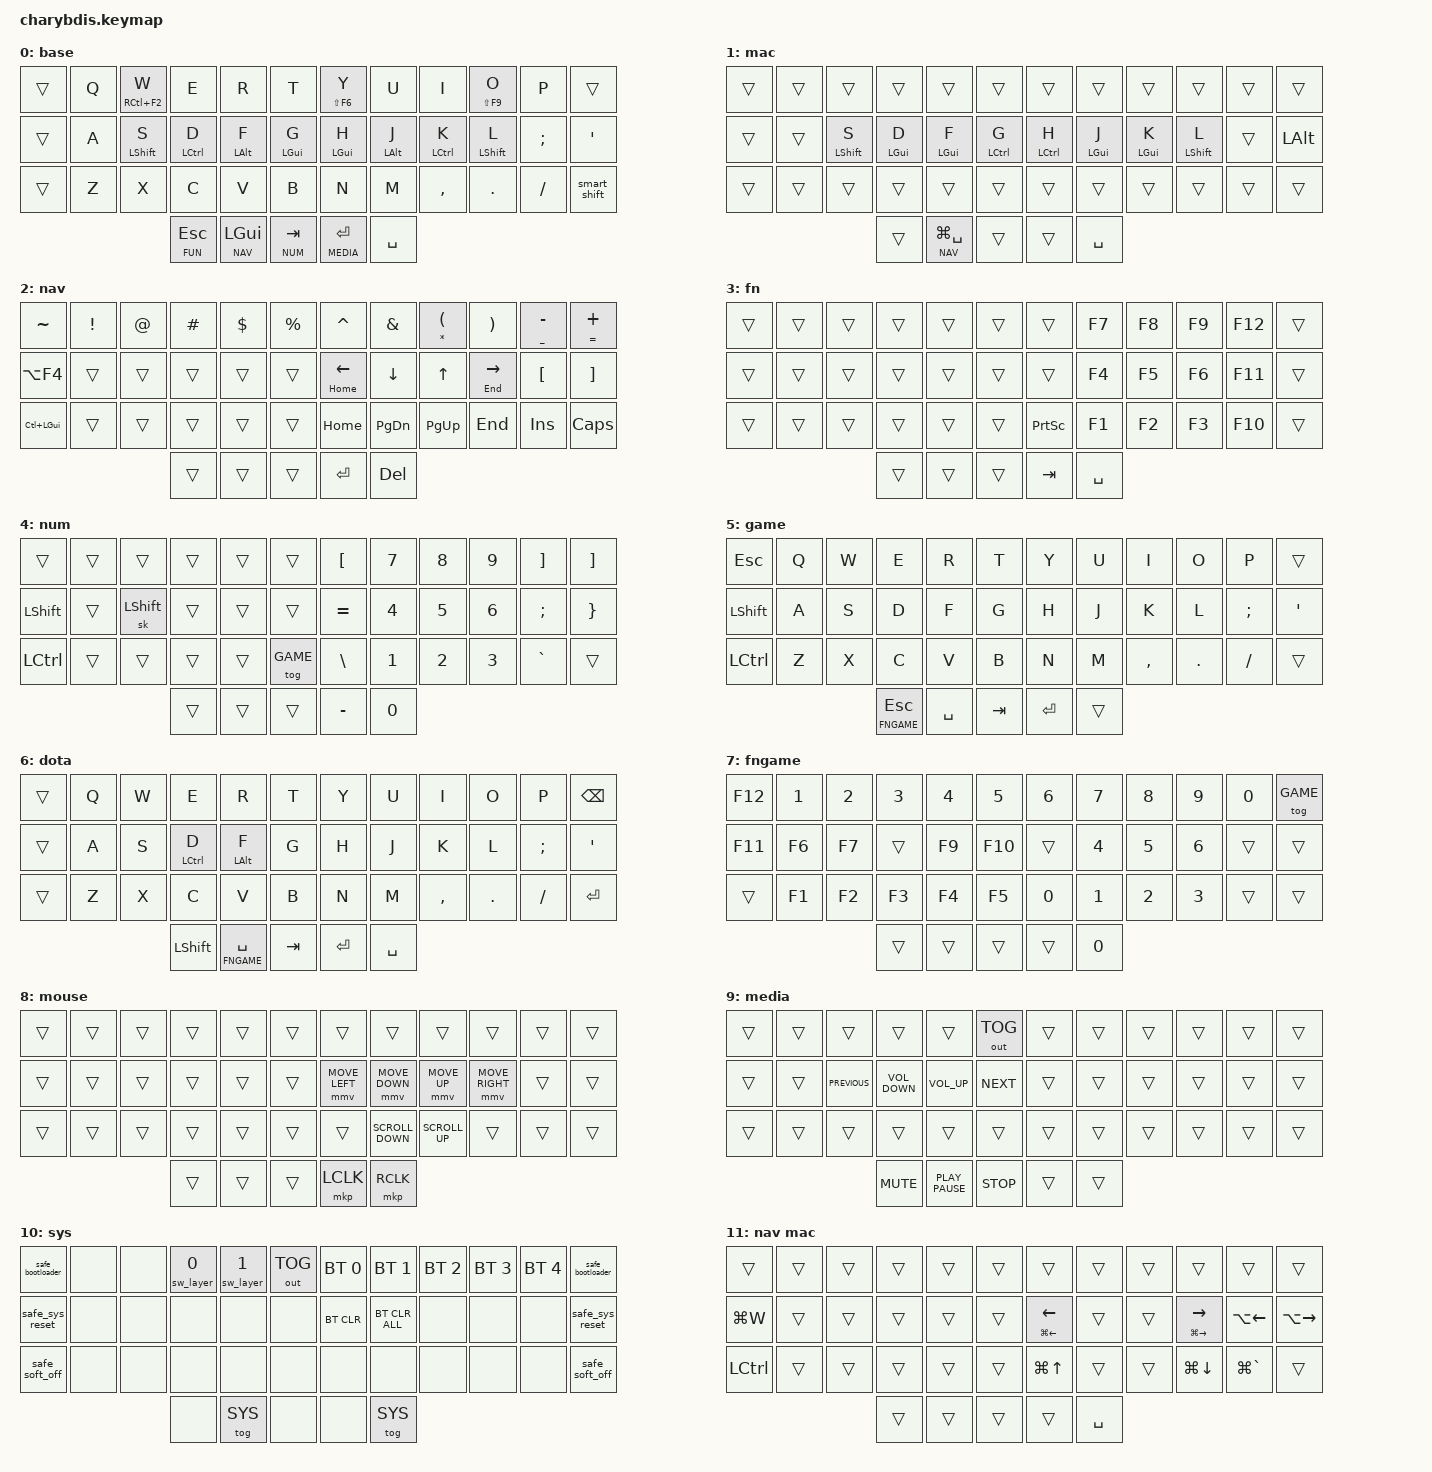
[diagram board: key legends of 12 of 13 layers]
/*
 * Copyright (c) 2020 The ZMK Contributors
 *
 * SPDX-License-Identifier: MIT
 *
 * Keymap do Charybdis Mini 3x6 (41 teclas), baseado no Corne
 * Documentação: https://zmk.dev/docs/keymaps
 */

// dt-formatter: indent="    ", multilineIntegerCellsIndent="keep"

// Port 41 teclas do Corne. A posição 41 não existe; os bindings dela
// viram combos nos polegares 39+40 (ver o nó combos no fim).
// Guia de montagem: docs/charybdis.md

#include <behaviors.dtsi>
#include <dt-bindings/zmk/bt.h>
#include <dt-bindings/zmk/keys.h>
#include <dt-bindings/zmk/outputs.h>
#include <dt-bindings/zmk/pointing.h>

// A ordem das layers é a precedência no ZMK: índice maior vence e &trans cai para o índice
// menor seguinte. A MAC fica logo acima da BASE (índice 1) de propósito: a BASE precisa
// continuar sendo a default (índice 0) e NAV/NUM/GAME/*game* precisam ficar ACIMA da MAC,
// senão ela sobrescreveria as setas da NAV (posições 18-21, que são a home row) e as letras
// puras da GAME/DOTA (14-21).

#define BASE 0
#define MAC 1
#define NAV 2
#define FUN 3
#define NUM 4
#define GAME 5
#define DOTA 6
#define FNGAME 7
#define MOUSE 8
#define MEDIA 9
#define SYS 10

// Variantes macOS das layers de navegação. Ficam no fim só para não renumerar as outras:
// quem manda é a precedência por índice (maior vence) e elas precisam ficar acima da NAV/FUN,
// que são suas "camadas de baixo". São ativadas por zmk,conditional-layers (ver o nó no fim).

#define NAV_MAC 11
#define FUN_MAC 12
#define QUICK_TAP_MS 175
#define SYS_CONFIRM_MS 300
#define KEYS_R 6 7 8 9 10 11 18 19 20 21 22 23 30 31 32 33 34 35
#define KEYS_L 0 1 2 3 4 5 12 13 14 15 16 17 24 25 26 27 28 29
#define THUMBS 39 40 36 37 38

// Igual a THUMBS, mas SEM o polegar do espaço (pos. 40): usado só na layer mac, onde
// mod+espaço é destrutivo no macOS (⌥␣ = espaço inquebrável, ⌃␣ = troca fonte de entrada)
// e o espaço "sumia" em rolls rápidos de digitação.

#define THUMBS_NO_SPACE 39 36 37 38

&mt {
    flavor = "tap-preferred";
    tapping-term-ms = <220>;
    quick-tap-ms = <220>;
    hold-trigger-key-positions = <0>;
};

&lt {
    flavor = "balanced";
    quick-tap-ms = <QUICK_TAP_MS>;
};

&sk {
    release-after-ms = <900>; // release-after 0.9s
    quick-release; // no double capitalizations
};

/ {
    behaviors {
        hml: homerow_mods_left {
            compatible = "zmk,behavior-hold-tap";
            label = "homerow_mods_left";
            bindings = <&kp>, <&kp>;

            #binding-cells = <2>;
            tapping-term-ms = <280>;
            quick-tap-ms = <175>;
            flavor = "balanced";
            hold-trigger-key-positions = <KEYS_R THUMBS>;
            hold-trigger-on-release;
            require-prior-idle-ms = <150>;
        };

        hmr: homerow_mods_right {
            compatible = "zmk,behavior-hold-tap";
            label = "HMR";
            bindings = <&kp>, <&kp>;

            #binding-cells = <2>;
            tapping-term-ms = <280>;
            quick-tap-ms = <QUICK_TAP_MS>;
            flavor = "balanced";
            hold-trigger-on-release;
            require-prior-idle-ms = <150>;
            hold-trigger-key-positions = <KEYS_L THUMBS>;
        };

        // Só na layer mac: idênticos a &hml/&hmr (mesmo tuning), mas o espaço não dispara
        // o hold. Assim `F`+espaço em roll vira "f" + " " (na ordem certa) em vez de
        // ⌥␣/⌃␣/⌘␣, que no macOS trocam a fonte de entrada, inserem NBSP ou abrem o Spotlight.

        hml_mac: homerow_mods_left_mac {
            compatible = "zmk,behavior-hold-tap";
            bindings = <&kp>, <&kp>;

            #binding-cells = <2>;
            tapping-term-ms = <280>;
            quick-tap-ms = <QUICK_TAP_MS>;
            flavor = "balanced";
            hold-trigger-on-release;
            require-prior-idle-ms = <150>;
            hold-trigger-key-positions = <KEYS_R THUMBS_NO_SPACE>;
        };

        hmr_mac: homerow_mods_right_mac {
            compatible = "zmk,behavior-hold-tap";
            bindings = <&kp>, <&kp>;

            #binding-cells = <2>;
            tapping-term-ms = <280>;
            quick-tap-ms = <QUICK_TAP_MS>;
            flavor = "balanced";
            hold-trigger-on-release;
            require-prior-idle-ms = <150>;
            hold-trigger-key-positions = <KEYS_L THUMBS_NO_SPACE>;
        };

        mt_home: mt_home {
            compatible = "zmk,behavior-hold-tap";
            label = "MT_HOME";
            bindings = <&kp>, <&kp>;

            #binding-cells = <2>;
            tapping-term-ms = <220>;
            quick-tap-ms = <220>;
            hold-trigger-key-positions = <0>;
            flavor = "tap-preferred";
        };

        bs_delete: bs_delete {
            compatible = "zmk,behavior-mod-morph";
            label = "BS_DELETE";
            bindings = <&kp BACKSPACE>, <&kp DEL>;

            #binding-cells = <0>;
            mods = <(MOD_LSFT|MOD_RSFT)>;
        };

        smart_shift: smart_shift {
            compatible = "zmk,behavior-mod-morph";
            label = "SMART_SHIFT";
            bindings = <&sk LEFT_SHIFT>, <&caps_word>;

            #binding-cells = <0>;
            mods = <(MOD_LSFT)>;
        };

        mt_end: mt_end {
            compatible = "zmk,behavior-hold-tap";
            label = "MT_END";
            bindings = <&kp>, <&kp>;

            #binding-cells = <2>;
            tapping-term-ms = <220>;
            quick-tap-ms = <220>;
            hold-trigger-key-positions = <0>;
            flavor = "tap-preferred";
        };

        copy_cut: copy_cut {
            compatible = "zmk,behavior-tap-dance";
            label = "COPY_CUT";
            #binding-cells = <0>;
            bindings = <&kp LC(INS)>, <&kp LC(X)>;
        };

        // macOS: mesma dança do &copy_cut, com os idiomas do sistema (⌘C copia, ⌘X recorta).

        copy_cut_mac: copy_cut_mac {
            compatible = "zmk,behavior-tap-dance";
            #binding-cells = <0>;
            bindings = <&kp LG(C)>, <&kp LG(X)>;
        };

        safe_bootloader: safe_bootloader {
            compatible = "zmk,behavior-tap-dance";
            #binding-cells = <0>;
            tapping-term-ms = <SYS_CONFIRM_MS>;
            bindings = <&none>, <&bootloader>;
        };

        safe_sys_reset: safe_sys_reset {
            compatible = "zmk,behavior-tap-dance";
            #binding-cells = <0>;
            tapping-term-ms = <SYS_CONFIRM_MS>;
            bindings = <&none>, <&sys_reset>;
        };

        safe_soft_off: safe_soft_off {
            compatible = "zmk,behavior-tap-dance";
            #binding-cells = <0>;
            tapping-term-ms = <SYS_CONFIRM_MS>;
            bindings = <&none>, <&soft_off>;
        };

        // Modo OS persistente (Linux/Windows <-> macOS), via módulo zmk-switch-layer.
        // O estado é gravado em settings, então sobrevive a reboot/power-off — o que &tog/&to
        // do ZMK não fazem (a MAC voltaria inativa a cada ciclo de energia, silenciosamente).
        // Parâmetro: 0 = Linux/Windows (source), 1 = macOS (target), 2 = alterna.
        // Com o modo em "macOS", a MAC é ativada EMPILHADA sobre a BASE — as layers
        // funcionais seguem por cima dela, então NAV/NUM/GAME/*game* não mudam de posição.

        sw_layer: sw_layer {
            compatible = "zmk-switch-layer,behavior-switch-layer-mode";
            #binding-cells = <1>;
            source-layer = <BASE>;
            target-layer = <MAC>;
        };
    };

    combos {
        compatible = "zmk,combos";

        dota {
            bindings = <&tog DOTA>;
            key-positions = <21 22>;
            layers = <GAME DOTA>;
        };

        // Copiar/recortar (X+C) e colar (C+V): cada idioma tem a sua variante e as máscaras
        // são disjuntas — o ZMK testa o combo contra a layer ativa MAIS ALTA, então no modo
        // mac só a variante _mac responde (e vice-versa). O caminho mod+letra (D+C = ⌘C)
        // continua valendo em qualquer layer, inclusive com NUM/GAME/MOUSE ativas.

        copy {
            bindings = <&copy_cut>;
            key-positions = <26 27>;
            layers = <BASE NUM GAME MOUSE>;
            require-prior-idle-ms = <150>;
        };

        paste {
            bindings = <&kp LS(INS)>;
            key-positions = <27 28>;
            layers = <BASE NUM GAME MOUSE>;
            timeout-ms = <18>;
            require-prior-idle-ms = <150>;
        };

        // Variantes macOS dos mesmos gestos (⌘C / ⌘X e ⌘V), só com a MAC ativa.

        copy_mac {
            bindings = <&copy_cut_mac>;
            key-positions = <26 27>;
            layers = <MAC>;
            require-prior-idle-ms = <150>;
        };

        paste_mac {
            bindings = <&kp LG(V)>;
            key-positions = <27 28>;
            layers = <MAC>;
            timeout-ms = <18>;
            require-prior-idle-ms = <150>;
        };

        mouse {
            bindings = <&tog MOUSE>;
            key-positions = <4 2>;
            layers = <BASE MAC GAME MOUSE>;
            require-prior-idle-ms = <150>;
        };

        alt+insert {
            bindings = <&kp LA(INSERT)>;
            key-positions = <15 16>;
            require-prior-idle-ms = <150>;
            layers = <BASE MAC>;
        };

        sys_left {
            bindings = <&tog SYS>;
            key-positions = <0 12>;
            layers = <BASE MAC>;
            timeout-ms = <35>;
            require-prior-idle-ms = <150>;
        };

        sys_right {
            bindings = <&tog SYS>;
            key-positions = <11 23>;
            layers = <BASE MAC>;
            timeout-ms = <35>;
            require-prior-idle-ms = <150>;
        };

        // Alterna o modo OS (Linux/Win <-> macOS) SEM passar pela SYS: aperte juntas as duas
        // pontas da coluna externa ESQUERDA (0 + 24, as duas células ▽). É o mesmo estado
        // persistente das teclas da SYS (&sw_layer), mas o gesto não envolve polegar nenhum —
        // era o polegar da SYS que ativava a NAV por acidente e transformava o espaço em DEL.

        os_toggle {
            bindings = <&sw_layer 2>;
            key-positions = <0 24>;
            layers = <BASE MAC>;
            timeout-ms = <35>;
            require-prior-idle-ms = <150>;
        };

        dongle_bootloader {
            bindings = <&bootloader>;
            key-positions = <1 2>;
            layers = <SYS>;
            timeout-ms = <50>;
            require-prior-idle-ms = <150>;
        };

        // O case de 41 teclas não tem a posição 41. Cada layer que usava a 41
        // reencontra o binding no combo dos dois polegares direitos (39 + 40).
        // BASE/MAC/GAME/FNGAME/MEDIA: BSPC/DEL (o &bs_delete original).
        // NAV: BSPC; FUN: APP; NUM: ponto; DOTA: F8; MOUSE: clique do meio.

        thumb_41_bs_del {
            bindings = <&bs_delete>;
            key-positions = <39 40>;
            layers = <BASE MAC GAME FNGAME MEDIA>;
            timeout-ms = <35>;
        };

        thumb_41_nav {
            bindings = <&kp BACKSPACE>;
            key-positions = <39 40>;
            layers = <NAV NAV_MAC>;
            timeout-ms = <35>;
        };

        thumb_41_fn {
            bindings = <&kp K_APPLICATION>;
            key-positions = <39 40>;
            layers = <FUN FUN_MAC>;
            timeout-ms = <35>;
        };

        thumb_41_num {
            bindings = <&kp DOT>;
            key-positions = <39 40>;
            layers = <NUM>;
            timeout-ms = <35>;
        };

        thumb_41_dota {
            bindings = <&kp F8>;
            key-positions = <39 40>;
            layers = <DOTA>;
            timeout-ms = <35>;
        };

        thumb_41_mouse {
            bindings = <&mkp MCLK>;
            key-positions = <39 40>;
            layers = <MOUSE>;
            timeout-ms = <35>;
        };

    };

    // Ativa as variantes macOS quando a layer mac está no modo macOS (MAC empilhada pelo
    // módulo zmk-switch-layer) e a NAV/FUN correspondente está segurada. As duas if-layers
    // precisam estar ativas ao mesmo tempo (é um AND, ver app/src/conditional_layer.c).

    conditional_layers {
        compatible = "zmk,conditional-layers";

        nav_mac {
            if-layers = <NAV MAC>;
            then-layer = <NAV_MAC>;
        };

        fun_mac {
            if-layers = <FUN MAC>;
            then-layer = <FUN_MAC>;
        };
    };

    keymap {
        compatible = "zmk,keymap";

        base {
            display-name = "base";

            // |  ▽  |  Q  | W/C-F2 |  E  |  R  |  T  |   | Y/S-F6 |  U  |  I  | O/S-F9 |  P  |  ▽   |
            // |  ▽  |  A  | S/SFT  |D/CTRL| F/ALT|G/GUI|   | H/GUI  |J/ALT|K/CTRL| L/SFT  |  ;  |  '   |
            // |  ▽  |  Z  |   X    |  C  |  V  |  B  |   |   N    |  M  |  ,  |   .    |  /  |SFT/CW|
            //                       |ESC/FN|GUI/NAV|TAB/NUM| |ENT/MED|SPACE|

            bindings = <
&trans  &kp Q  &mt RC(F2) W       &kp E                &kp R             &kp T              &mt LS(F6) Y     &kp U            &kp I                &mt LS(F9) O       &kp P     &trans
&trans  &kp A  &hml LEFT_SHIFT S  &hml LEFT_CONTROL D  &hml LEFT_ALT F   &hml LEFT_GUI G    &hmr LEFT_GUI H  &hmr LEFT_ALT J  &hmr LEFT_CONTROL K  &hmr LEFT_SHIFT L  &kp SEMI  &kp SQT
&trans  &kp Z  &kp X              &kp C                &kp V             &kp B              &kp N            &kp M            &kp COMMA            &kp DOT            &kp FSLH  &smart_shift
                                  &lt FUN ESCAPE       &lt NAV LEFT_GUI  &lt NUM TAB        &lt MEDIA ENTER  &kp SPACE
            >;
        };

        // Layer diferencial para hosts macOS (perfil BT_SEL 0). As células ▽ herdam a BASE,
        // então só a home row é redefinida aqui.
        // REGRA: o MESMO dedo dispara a MESMA ação nos dois SOs.
        //   anelar    (15/20) Ctrl no Linux  -> Cmd no macOS   (Ctrl+T -> ⌘T, Ctrl+C-> ⌘C)
        //   médio     (16/19) Alt no Linux   -> Cmd no macOS   (Alt+Tab -> ⌘Tab, Alt+F4 -> ⌘W)
        //   indicador (17/18) Super no Linux -> Ctrl no macOS  (terminal: Ctrl+C/A/E/K)
        //   polegar 38/40: Tab e espaço seguem iguais -> ⌘Tab sai com o mesmo gesto do Alt+Tab
        //   ⌥ (Option) fica na coluna externa direita (23): acentos (⌥e = ´, ⌥c = ç) e ⌥+seta.
        //   A NAV mac dá atalhos dedicados de palavra/início de linha, então não é preciso
        //   segurar ⌥ para navegar.
        // Mods: &hml_mac/&hmr_mac = &hml/&hmr com o espaço fora do hold-trigger (ver THUMBS_NO_SPACE).
        // Apelidos curtos (LGUI/LCTRL/LSHFT) só para caber no alinhamento de colunas deste arquivo.
        // |  ▽   |  ▽  | S/SFT  | D/⌘   | F/⌘   | G/CTRL |   | H/CTRL | J/⌘  | K/⌘   | L/SFT  |  ▽  |  ⌥   |

        mac {
            display-name = "mac";
            bindings = <
&trans  &trans  &trans            &trans           &trans             &trans              &trans            &trans           &trans           &trans            &trans  &trans
&trans  &trans  &hml_mac LSHFT S  &hml_mac LGUI D  &hml_mac LGUI F    &hml_mac LCTRL G    &hmr_mac LCTRL H  &hmr_mac LGUI J  &hmr_mac LGUI K  &hmr_mac LSHFT L  &trans  &kp LALT
&trans  &trans  &trans            &trans           &trans             &trans              &trans            &trans           &trans           &trans            &trans  &trans
                                  &trans           &lt NAV LG(SPACE)  &trans              &trans            &kp SPACE
            >;
        };

        navigation {
            display-name = "nav";

            // |  ~  |  !  |  @  |  #  |  $  |  %  |   |  ^   |  &  |  (/* |  )  |  -/_ |  +/= |
            // |A-F4 |  ▽  |  ▽  |  ▽  |  ▽  |  ▽  |   |←/HOME|  ↓  |  ↑   |→/END|  [   |   ]  |
            // |C-GUI|  ▽  |  ▽  |  ▽  |  ▽  |  ▽  |   | HOME |PGDN | PGUP | END  | INS  | CAPS |
            //                    |  ▽  |  ▽  |  ▽  |   | ENTER| DEL |

            bindings = <
&kp TILDE         &kp EXCL  &kp AT  &kp HASH  &kp DOLLAR  &kp PERCENT    &kp CARET           &kp AMPERSAND  &mt ASTERISK LEFT_PARENTHESIS  &kp RIGHT_PARENTHESIS  &mt UNDER MINUS   &mt EQUAL PLUS
&kp LA(F4)        &trans    &trans  &trans    &trans      &trans         &mt_home HOME LEFT  &kp DOWN       &kp UP                         &mt_end END RIGHT      &kp LEFT_BRACKET  &kp RIGHT_BRACKET
&kp LC(LEFT_GUI)  &trans    &trans  &trans    &trans      &trans         &kp HOME            &kp PAGE_DOWN  &kp PAGE_UP                    &kp END                &kp INSERT        &kp CAPSLOCK
                                    &trans    &trans      &trans         &kp RET             &kp DEL
            >;
        };

        function {
            display-name = "fn";

            // |  ▽  |  ▽  |  ▽  |  ▽  |  ▽  |  ▽  |   |  ▽  | F7 | F8 | F9 | F12|  ▽  |
            // |  ▽  |  ▽  |  ▽  |  ▽  |  ▽  |  ▽  |   |  ▽  | F4 | F5 | F6 | F11|  ▽  |
            // |  ▽  |  ▽  |  ▽  |  ▽  |  ▽  |  ▽  |   |PSCRN| F1 | F2 | F3 | F10|  ▽  |
            //                    |  ▽  |  ▽  |  ▽  |   | TAB |SPACE|   (39+40 = APP)

            bindings = <
&trans  &trans  &trans  &trans  &trans  &trans    &trans           &kp F7     &kp F8             &kp F9  &kp F12  &trans
&trans  &trans  &trans  &trans  &trans  &trans    &trans           &kp F4     &kp F5             &kp F6  &kp F11  &trans
&trans  &trans  &trans  &trans  &trans  &trans    &kp PRINTSCREEN  &kp F1     &kp F2             &kp F3  &kp F10  &trans
                        &trans  &trans  &trans    &kp TAB          &kp SPACE
            >;
        };

        numbers {
            display-name = "num";

            // |  ▽  |  ▽  |  ▽  |  ▽  |  ▽  |  ▽  |   |  [  |  7  |  8  |  9  |  ]  |  ]  |
            // | SFT |  ▽  |SK-SFT|  ▽  |  ▽  |  ▽  |   |  =  |  4  |  5  |  6  |  {  |  }  |
            // |CTRL |  ▽  |  ▽  |  ▽  |  ▽  | GAME|   |  \  |  1  |  2  |  3  | KP, |  ▽  |
            //                    |  ▽  |  ▽  |  ▽  |   |  -  |  0  |

            bindings = <
&trans     &trans  &trans          &trans  &trans  &trans       &kp LEFT_BRACKET  &kp N7        &kp N8   &kp N9  &kp RIGHT_BRACKET  &kp RIGHT_BRACKET
&kp LSHFT  &trans  &sk LEFT_SHIFT  &trans  &trans  &trans       &kp EQUAL         &kp N4        &kp N5   &kp N6  &kp SEMI           &kp RIGHT_BRACE
&kp LCTRL  &trans  &trans          &trans  &trans  &tog GAME    &kp BACKSLASH     &kp N1        &kp N2   &kp N3  &kp GRAVE          &trans
                                   &trans  &trans  &trans       &kp MINUS         &kp NUMBER_0
            >;
        };

        game {
            display-name = "game";

            // | ESC |  Q  |  W  |  E  |  R  |  T  |   |  Y  |  U  |  I  |  O  |  P  |  ▽  |
            // | SFT |  A  |  S  |  D  |  F  |  G  |   |  H  |  J  |  K  |  L  |  ;  |  '  |
            // |CTRL |  Z  |  X  |  C  |  V  |  B  |   |  N  |  M  |  ,  |  .  |  /  |  ▽  |
            //                    |ESC/FNG|SPACE| TAB |   |ENTER|  ▽  |

            bindings = <
&kp ESC    &kp Q  &kp W  &kp E           &kp R      &kp T      &kp Y    &kp U   &kp I      &kp O    &kp P     &trans
&kp LSHFT  &kp A  &kp S  &kp D           &kp F      &kp G      &kp H    &kp J   &kp K      &kp L    &kp SEMI  &kp SQT
&kp LCTRL  &kp Z  &kp X  &kp C           &kp V      &kp B      &kp N    &kp M   &kp COMMA  &kp DOT  &kp FSLH  &trans
                         &lt FNGAME ESC  &kp SPACE  &kp TAB    &kp RET  &trans
            >;
        };

        dota {
            display-name = "dota";

            // |  ▽  |  Q  |  W  |  E  |  R  |  T  |   |  Y  |  U  |  I  |  O  |  P  |BSPC |
            // |  ▽  |  A  |  S  |D/CTRL|F/ALT|  G  |   |  H  |  J  |  K  |  L  |  ;  |  '  |
            // |  ▽  |  Z  |  X  |  C  |  V  |  B  |   |  N  |  M  |  ,  |  .  |  /  |ENTER|
            //                    | SFT |SPC/FNG| TAB |   |ENTER|SPACE|

            bindings = <
&trans  &kp Q  &kp W  &kp E                &kp R             &kp T      &kp Y    &kp U      &kp I      &kp O    &kp P     &kp BACKSPACE
&trans  &kp A  &kp S  &hml LEFT_CONTROL D  &hml LEFT_ALT F   &kp G      &kp H    &kp J      &kp K      &kp L    &kp SEMI  &kp SQT
&trans  &kp Z  &kp X  &kp C                &kp V             &kp B      &kp N    &kp M      &kp COMMA  &kp DOT  &kp FSLH  &kp ENTER
                      &kp LEFT_SHIFT       &lt FNGAME SPACE  &kp TAB    &kp RET  &kp SPACE
            >;
        };

        fngame {
            display-name = "fngame";

            // | F12 |  1  |  2  |  3  |  4  |  5  |   |  6  |  7  |  8  |  9  |  0  | GAME|
            // | F11 | F6  | F7  | F8  | F9  | F10 |   |  ▽  |  4  |  5  |  6  |  ▽  |  ▽  |
            // |  ▽  | F1  | F2  | F3  | F4  | F5  |   |  0  |  1  |  2  |  3  |  ▽  |  ▽  |
            //                    |  ▽  |  ▽  |  ▽  |   |  ▽  |  0  |

            bindings = <
&kp F12  &kp N1  &kp N2  &kp N3  &kp N4  &kp N5     &kp N6  &kp N7        &kp N8  &kp N9  &kp N0  &tog GAME
&kp F11  &kp F6  &kp F7  &trans  &kp F9  &kp F10    &trans  &kp N4        &kp N5  &kp N6  &trans  &trans
&trans   &kp F1  &kp F2  &kp F3  &kp F4  &kp F5     &kp N0  &kp N1        &kp N2  &kp N3  &trans  &trans
                         &trans  &trans  &trans     &trans  &kp NUMBER_0
            >;
        };

        mouse {
            display-name = "mouse";

            // |  ▽  |  ▽  |  ▽  |  ▽  |  ▽  |  ▽  |   |  ▽  |  ▽  |  ▽  |  ▽  |  ▽  |  ▽  |
            // |  ▽  |  ▽  |  ▽  |  ▽  |  ▽  |  ▽  |   | M←  | M↓  | M↑  | M→  |  ▽  |  ▽  |
            // |  ▽  |  ▽  |  ▽  |  ▽  |  ▽  |  ▽  |   |  ▽  |  ▽  |  ▽  |  ▽  |  ▽  |  ▽  |
            //                    |  ▽  |  ▽  |  ▽  |   |LCLK |RCLK |   (39+40 = MCLK)

            bindings = <
&trans  &trans  &trans  &trans  &trans  &trans    &trans          &trans             &trans           &trans           &trans  &trans
&trans  &trans  &trans  &trans  &trans  &trans    &mmv MOVE_LEFT  &mmv MOVE_DOWN     &mmv MOVE_UP     &mmv MOVE_RIGHT  &trans  &trans
&trans  &trans  &trans  &trans  &trans  &trans    &trans          &kp K_SCROLL_DOWN  &kp K_SCROLL_UP  &trans           &trans  &trans
                        &trans  &trans  &trans    &mkp LCLK       &mkp RCLK
            >;
        };

        media {
            display-name = "media";

            // |  ▽  |  ▽  |  ▽  |  ▽  |  ▽  | OUT |   |  ▽  |  ▽  |  ▽  |  ▽  |  ▽  |  ▽  |
            // |  ▽  |  ▽  |NEXT |VOL+ |VOL- |PREV |   |  ▽  |  ▽  |  ▽  |  ▽  |  ▽  |  ▽  |
            // |  ▽  |  ▽  |  ▽  |  ▽  |  ▽  |  ▽  |   |  ▽  |  ▽  |  ▽  |  ▽  |  ▽  |  ▽  |
            //                    |MUTE |PLAY |STOP |   |  ▽  |  ▽  |

            bindings = <
&trans  &trans  &trans          &trans             &trans            &out OUT_TOG    &trans  &trans  &trans  &trans  &trans  &trans
&trans  &trans  &kp K_PREVIOUS  &kp C_VOLUME_DOWN  &kp C_VOLUME_UP   &kp K_NEXT      &trans  &trans  &trans  &trans  &trans  &trans
&trans  &trans  &trans          &trans             &trans            &trans          &trans  &trans  &trans  &trans  &trans  &trans
                                &kp K_MUTE         &kp K_PLAY_PAUSE  &kp K_STOP      &trans  &trans
            >;
        };

        system {
            display-name = "sys";

            // |2BOOT-L| DBL | DBL |LIN/W| MAC | OUT |   | BT1 | BT2 | BT3 | BT4 | BT5 |2BOOT-R|
            // |2RST-L |  ·  |  ·  |  ·  |  ·  |  ·  |   | CLR |CLR-A|  ·  |  ·  |  ·  |2RST-R |
            // |2OFF   |  ·  |  ·  |  ·  |  ·  |  ·  |   |  ·  |  ·  |  ·  |  ·  |  ·  |2OFF   |
            //                     |  ·  | EXIT|  ·  |   |  ·  | EXIT|

            bindings = <
&safe_bootloader  &none  &none  &sw_layer 0  &sw_layer 1  &out OUT_TOG    &bt BT_SEL 0  &bt BT_SEL 1    &bt BT_SEL 2  &bt BT_SEL 3  &bt BT_SEL 4  &safe_bootloader
&safe_sys_reset   &none  &none  &none        &none        &none           &bt BT_CLR    &bt BT_CLR_ALL  &none         &none         &none         &safe_sys_reset
&safe_soft_off    &none  &none  &none        &none        &none           &none         &none           &none         &none         &none         &safe_soft_off
                                &none        &tog SYS     &none           &none         &tog SYS
            >;
        };

        // Variante macOS da NAV, ativada automaticamente por zmk,conditional-layers quando
        // NAV e MAC estão ativas ao mesmo tempo (ver o nó conditional_layers no fim do arquivo).
        // Só o que difere da NAV; o resto cai na NAV via &trans.
        //  12      ⌘W (fecha janela/aba)          18/21  hold = ⌘←/⌘→ (início/fim de linha)
        //  22/23   ⌥←/⌥→ (palavra)                30/33  ⌘↑/⌘↓ (início/fim do documento)
        //  24      Ctrl (com as setas: Ctrl+←/→ troca de Space, Ctrl+↑ = Mission Control)
        //  34      ⌘` (alterna janelas do mesmo app — o Insert do Linux não existe no macOS)
        //  40      espaço (mesmo com a NAV segurada: o DEL da NAV não passa para o modo mac)
        //  Os colchetes [ ] das posições 22/23 continuam disponíveis na NUMPAD/NUM (6/10).

        nav_mac {
            display-name = "nav mac";
            bindings = <
&trans     &trans  &trans  &trans  &trans  &trans    &trans                  &trans     &trans  &trans                   &trans         &trans
&kp LG(W)  &trans  &trans  &trans  &trans  &trans    &mt_home LG(LEFT) LEFT  &trans     &trans  &mt_end LG(RIGHT) RIGHT  &kp LA(LEFT)   &kp LA(RIGHT)
&kp LCTRL  &trans  &trans  &trans  &trans  &trans    &kp LG(UP)              &trans     &trans  &kp LG(DOWN)             &kp LG(GRAVE)  &trans
                           &trans  &trans  &trans    &trans                  &kp SPACE
            >;
        };

        // Variante macOS da FUN, ativada por zmk,conditional-layers quando FUN e MAC estão
        // ativas juntas. O PrintScreen do Linux não existe no macOS: vira ⌘⇧3 (tela toda) em
        // 30 e ⌘⇧4 (região) em 11.

        fun_mac {
            display-name = "fn mac";
            bindings = <
&trans  &trans  &trans  &trans  &trans  &trans    &trans          &trans  &trans  &trans  &trans  &kp LG(LS(N4))
&trans  &trans  &trans  &trans  &trans  &trans    &trans          &trans  &trans  &trans  &trans  &trans
&trans  &trans  &trans  &trans  &trans  &trans    &kp LG(LS(N3))  &trans  &trans  &trans  &trans  &trans
                        &trans  &trans  &trans    &trans          &trans
            >;
        };
    };
};

/* vim: set ft=c tw=146: */
